VERSION ""

NS_ :

BS_:

BU_: Veh
VAL_TABLE_ OverFault_Value_Table 1 "故障" 0 "正常" ;
VAL_TABLE_ WorkState_Value_Table 2 "辅机正常" 1 "辅机故障" 0 "辅机不工作" ;
VAL_TABLE_ WorkLight_Value_Table 2 "发电正常" 1 "发电故障" 0 "不发电" ;

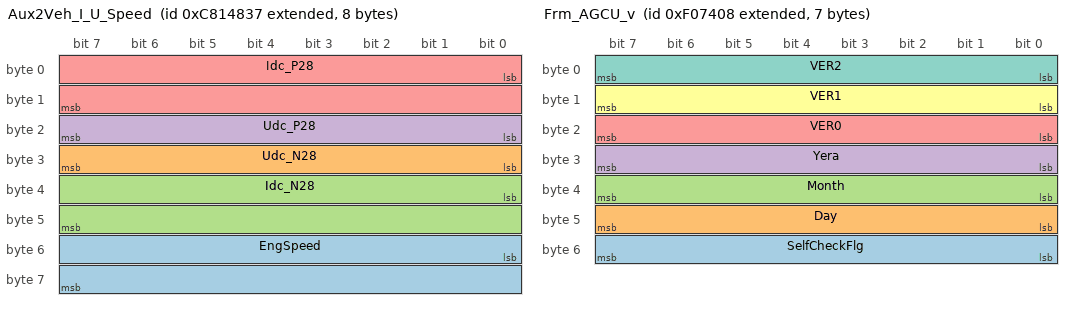
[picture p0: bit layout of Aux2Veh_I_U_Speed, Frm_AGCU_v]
BO_ 2357282871 Aux2Veh_I_U_Speed: 8 Veh
 SG_ EngSpeed : 48|16@1+ (1,0) [0|0] "" Vector__XXX
 SG_ Udc_N28 : 24|8@1+ (1,0) [0|0] "" Vector__XXX
 SG_ Idc_N28 : 32|16@1+ (1,0) [0|0] "" Vector__XXX
 SG_ Udc_P28 : 16|8@1+ (1,0) [0|0] "" Vector__XXX
 SG_ Idc_P28 : 0|16@1+ (1,0) [0|0] "" Vector__XXX

BO_ 2163241992 Frm_AGCU_v: 7 Veh
 SG_ SelfCheckFlg : 48|8@1+ (1,0) [0|0] "" Vector__XXX
 SG_ Day : 40|8@1+ (1,0) [0|0] "" Vector__XXX
 SG_ Month : 32|8@1+ (1,0) [0|0] "" Vector__XXX
 SG_ Yera : 24|8@1+ (1,2000) [0|0] "" Vector__XXX
 SG_ VER0 : 16|8@1+ (1,0) [0|0] "" Vector__XXX
 SG_ VER1 : 8|8@1+ (1,0) [0|0] "" Vector__XXX
 SG_ VER2 : 0|8@1+ (1,0) [0|0] "" Vector__XXX

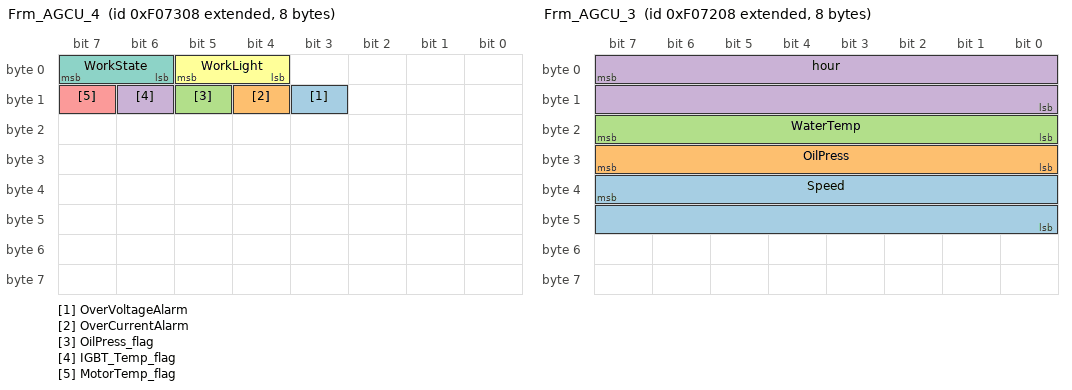
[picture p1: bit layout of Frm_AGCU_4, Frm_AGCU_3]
BO_ 2163241736 Frm_AGCU_4: 8 Veh
 SG_ OverVoltageAlarm : 11|1@0+ (1,0) [0|0] "" Vector__XXX
 SG_ OverCurrentAlarm : 12|1@0+ (1,0) [0|0] "" Vector__XXX
 SG_ OilPress_flag : 13|1@0+ (1,0) [0|0] "" Vector__XXX
 SG_ IGBT_Temp_flag : 14|1@0+ (1,0) [0|0] "" Vector__XXX
 SG_ MotorTemp_flag : 15|1@0+ (1,0) [0|0] "" Vector__XXX
 SG_ WorkLight : 5|2@0+ (1,0) [0|0] "" Vector__XXX
 SG_ WorkState : 7|2@0+ (1,0) [0|0] "" Vector__XXX

BO_ 2163241480 Frm_AGCU_3: 8 Veh
 SG_ Speed : 39|16@0+ (1,0) [0|0] "" Vector__XXX
 SG_ OilPress : 31|8@0+ (4,0) [0|0] "" Vector__XXX
 SG_ WaterTemp : 23|8@0+ (1,-50) [0|0] "" Vector__XXX
 SG_ hour : 7|16@0+ (0.1,0) [0|0] "" Vector__XXX

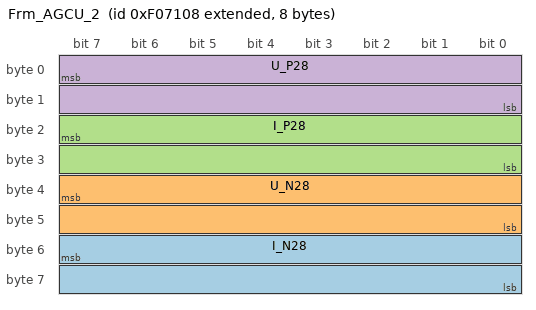
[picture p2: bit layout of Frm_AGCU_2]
BO_ 2163241224 Frm_AGCU_2: 8 Veh
 SG_ I_N28 : 55|16@0+ (0.1,0) [0|0] "" Vector__XXX
 SG_ U_N28 : 39|16@0+ (0.1,0) [0|0] "" Vector__XXX
 SG_ I_P28 : 23|16@0+ (0.1,0) [0|0] "" Vector__XXX
 SG_ U_P28 : 7|16@0+ (0.1,0) [0|0] "" Vector__XXX

CM_ SG_ 2163241736 OverVoltageAlarm "过压报警";
CM_ SG_ 2163241736 OverCurrentAlarm "过流报警";
CM_ SG_ 2163241736 OilPress_flag "油压报警";
CM_ SG_ 2163241736 IGBT_Temp_flag "控制器过温报警";
CM_ SG_ 2163241736 MotorTemp_flag "发动机过温报警";
CM_ SG_ 2163241736 WorkLight "0-不发电
1-发电故障
2-发电正常";
CM_ SG_ 2163241736 WorkState "0-辅机不工作
1-辅机故障
2-辅机正常";
BA_DEF_ SG_  "SigType" ENUM  "Default","Range","RangeSigned","ASCII","Discrete","Control","ReferencePGN","DTC","StringDelimiter","StringLength","StringLengthControl";
BA_DEF_ SG_  "GenSigEVName" STRING ;
BA_DEF_ SG_  "GenSigILSupport" ENUM  "No","Yes";
BA_DEF_ SG_  "GenSigSendType" ENUM  "Cyclic","OnWrite","OnWriteWithRepetition","OnChange","OnChangeWithRepetition","IfActive","IfActiveWithRepetition","NoSigSendType";
BA_DEF_ BO_  "GenMsgILSupport" ENUM  "No","Yes";
BA_DEF_ BU_  "NmStationAddress" INT 0 255;
BA_DEF_ BO_  "GenMsgSendType" ENUM  "cyclic","NotUsed","IfActive","NotUsed","NotUsed","NotUsed","NotUsed","NotUsed","noMsgSendType";
BA_DEF_ BO_  "GenMsgRequestable" INT 0 1;
BA_DEF_  "DBName" STRING ;
BA_DEF_  "BusType" STRING ;
BA_DEF_  "ProtocolType" STRING ;
BA_DEF_ BO_  "VFrameFormat" ENUM  "StandardCAN","ExtendedCAN","reserved","J1939PG";
BA_DEF_DEF_  "SigType" "Default";
BA_DEF_DEF_  "GenSigEVName" "Env@Nodename_@Signame";
BA_DEF_DEF_  "GenSigILSupport" "Yes";
BA_DEF_DEF_  "GenSigSendType" "NoSigSendType";
BA_DEF_DEF_  "GenMsgILSupport" "Yes";
BA_DEF_DEF_  "NmStationAddress" 254;
BA_DEF_DEF_  "GenMsgSendType" "noMsgSendType";
BA_DEF_DEF_  "GenMsgRequestable" 1;
BA_DEF_DEF_  "DBName" "";
BA_DEF_DEF_  "BusType" "CAN";
BA_DEF_DEF_  "ProtocolType" "J1939";
BA_DEF_DEF_  "VFrameFormat" "J1939PG";
BA_ "DBName" "__K_TTcan";
VAL_ 2163241992 SelfCheckFlg 1 "故障" 0 "正常" ;
VAL_ 2163241736 OverVoltageAlarm 1 "故障" 0 "正常" ;
VAL_ 2163241736 OverCurrentAlarm 1 "故障" 0 "正常" ;
VAL_ 2163241736 OilPress_flag 1 "故障" 0 "正常" ;
VAL_ 2163241736 IGBT_Temp_flag 1 "故障" 0 "正常" ;
VAL_ 2163241736 MotorTemp_flag 1 "故障" 0 "正常" ;
VAL_ 2163241736 WorkLight 2 "发电正常" 1 "发电故障" 0 "不发电" ;
VAL_ 2163241736 WorkState 2 "辅机正常" 1 "辅机故障" 0 "辅机不工作" ;
